# Timer_Port_1 register map
Vendor: Texas Instruments
Peripheral module from a debugger description file (folder msp430).
Registers are 8-bit, read-write, reset 0x0 unless marked. A register's access mark holds for its fields unless they carry their own. Offsets are as the file gives them; lines under a group give offsets from that group; [hi:lo] are bit positions; {n}, {i} and the like mark numbered series; 'fields as' and 'values as' point back to an identical list; <NAME> marks a mode.

## Timer/Port
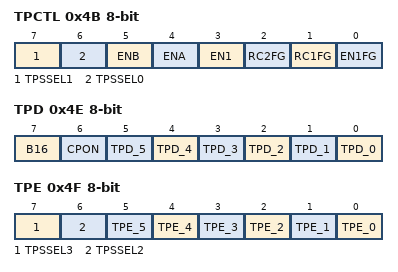
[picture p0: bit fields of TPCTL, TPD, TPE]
0x4B TPCTL — Timer/Port Control
  [7] TPSSEL1, [6] TPSSEL0, [5] ENB, [4] ENA, [3] EN1, [2] RC2FG, [1] RC1FG, [0] EN1FG
0x4C TPCNT1 access not given reset not defined — Timer/Port Counter 1
0x4D TPCNT2 access not given reset not defined — Timer/Port Counter 2
0x4E TPD — Timer/Port Data
  [7] B16, [6] CPON, [n] TPD_{n} (n=0..5)
0x4F TPE — Timer/Port Enable
  [7] TPSSEL3, [6] TPSSEL2, [n] TPE_{n} (n=0..5)
